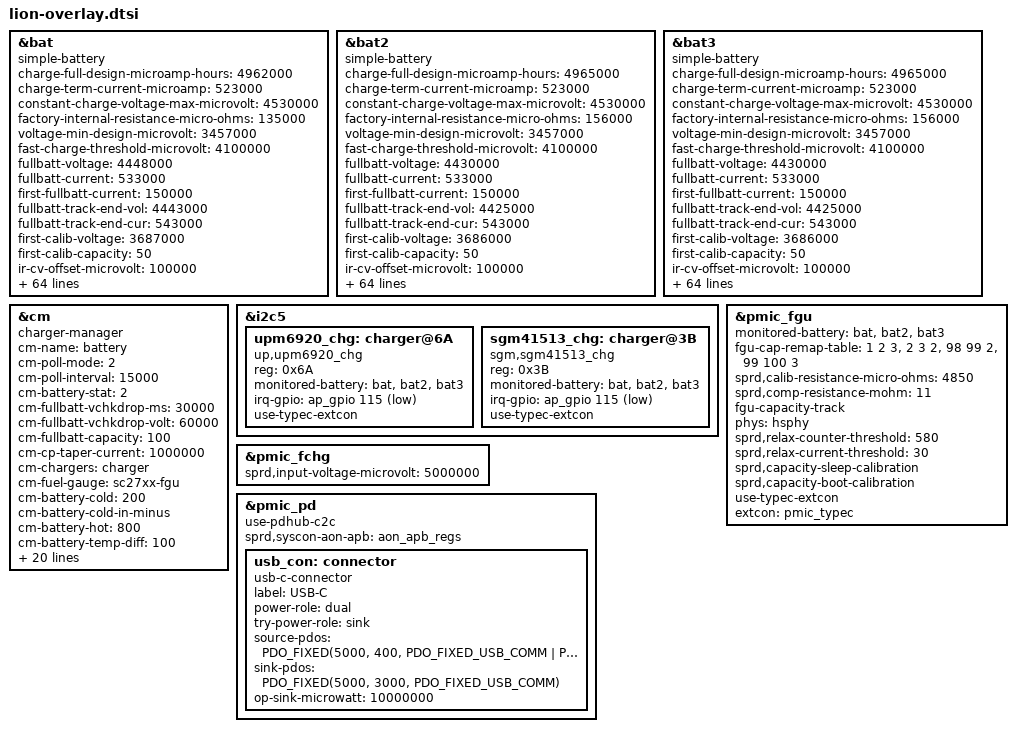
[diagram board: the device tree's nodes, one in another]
// SPDX-License-Identifier: GPL-2.0-only
/*
 * Unisoc Qogirl6 platform DTS file
 *
 * Copyright (C) 2020, Unisoc Inc.
 */

#include <dt-bindings/usb/pd.h>

&bat {
	compatible = "simple-battery";
	status = "okay";
	charge-full-design-microamp-hours = <4962000>;
	charge-term-current-microamp = <523000>;
	constant-charge-voltage-max-microvolt = <4530000>;
	factory-internal-resistance-micro-ohms = <135000>;
	voltage-min-design-microvolt = <3457000>;

	fast-charge-threshold-microvolt = <4100000>;
	fullbatt-voltage = <4448000>;
	fullbatt-current = <533000>;
	first-fullbatt-current = <150000>;
	fullbatt-track-end-vol = <4443000>;
	fullbatt-track-end-cur = <543000>;
	first-calib-voltage = <3687000>;
	first-calib-capacity = <50>;

	ir-cv-offset-microvolt = <100000>;
	ir-rc-micro-ohms = <0>;
	ir-us-upper-limit-microvolt = <4624000>;

	ocv-capacity-celsius = <25>;
	ocv-capacity-table-0 = <4448000 100>, <4384000 95>, <4331000 90>,
				<4273000 85>, <4212000 80>, <4153000 75>,
				<4096000 70>, <4044000 65>, <3997000 60>,
				<3945000 55>, <3890000 50>, <3859000 45>,
				<3835000 40>, <3815000 35>, <3799000 30>,
				<3777000 25>, <3754000 20>, <3730000 15>,
				<3697000 10>, <3687000 5>, <3400000 0>;
	voltage-temp-table = <1491668 600>,<1404493 650>,<1307738 700>,
				<1203814 750>, <1095466 800>, <986112 850>,
				<878559 900>,<775113 950>,<678460 1000>,
				<590240 1050>, <510773 1100>, <440156 1150>,
				<378279 1200>, <324561 1250>, <278079 1300>,
				<238260 1350>, <204267 1400>, <175208 1450>,
				<150460 1500>, <129410 1550>, <111497 1600>,
				<96484 1650>, <83710 1700>, <72772 1750>,
				<63423 1800>,<55444 1850>,<48599 1900>;

	capacity-temp-table = <45 96>, <25 100>, <10 100>, <0 93>, <(-10) 88>;
	resistance-temp-table = <45 88>, <25 100>, <10 143>, <0 976>, <(-10) 1049>;
	charge-sdp-current-microamp = <500000 500000>;
	charge-dcp-current-microamp = <3200000 3200000>;
	charge-cdp-current-microamp = <1500000 1500000>;
	charge-unknown-current-microamp = <1050000 1050000>;
	charge-fchg-current-microamp = <3480000 3000000>;

	cap-calib-energy-density-ocv-table = <3350000 3680000>, <4130000 4500000>;
	cap-track-energy-density-ocv-table = <3400000 3687000>;

	dcp-jeita-temp-table = <800 830 0 4200000>,<1000 1003 1000000 4200000>, <1100 1103 3200000 4500000>,
		<1150 1153 3200000 4500000>,<1450 1453 3200000 4530000>, <1600 1570 3200000 4200000>;
	sdp-jeita-temp-table = <800 803 0 4200000>,<1000 1003 500000 4200000>, <1100 1103 500000 4500000>,
		<1150 1153 500000 4500000>,<1450 1453 500000 4530000>, <1600 1570 500000 4200000>;
	cdp-jeita-temp-table = <800 830 0 4200000>,<1000 1030 1000000 4200000>, <1100 1103 1500000 4500000>,
		<1150 1153 1500000 4500000>,<1450 1453 1500000 4530000>, <1600 1570 1500000 4200000>;
	unknown-jeita-temp-table =<800 830 0 4200000>, <1000 1003 1000000 4200000>, <1100 1103 2000000 4500000>,
		<1150 1153 3000000 4500000>,<1450 1453 2000000 4530000>, <1600 1570 2000000 4200000>;
	fchg-jeita-temp-table =<800 830 0 4200000>,  <1000 1003 1000000 4200000>, <1100 1103 3000000 4500000>,
		<1150 1153 3480000 4500000>,<1450 1453 3480000 4530000>, <1600 1570 3480000 4200000>;
};

&bat2 {
	compatible = "simple-battery";
	status = "okay";
	charge-full-design-microamp-hours = <4965000>;
	charge-term-current-microamp = <523000>;
	constant-charge-voltage-max-microvolt = <4530000>;
	factory-internal-resistance-micro-ohms = <156000>;
	voltage-min-design-microvolt = <3457000>;

	fast-charge-threshold-microvolt = <4100000>;
	fullbatt-voltage = <4430000>;
	fullbatt-current = <533000>;
	first-fullbatt-current = <150000>;
	fullbatt-track-end-vol = <4425000>;
	fullbatt-track-end-cur = <543000>;
	first-calib-voltage = <3686000>;
	first-calib-capacity = <50>;

	ir-cv-offset-microvolt = <100000>;
	ir-rc-micro-ohms = <0>;
	ir-us-upper-limit-microvolt = <4624000>;

	ocv-capacity-celsius = <25>;
	ocv-capacity-table-0 = <4430000 100>, <4375000 95>, <4321000 90>,
				<4261000 85>, <4199000 80>, <4139000 75>,
				<4083000 70>, <4032000 65>, <3983000 60>,
				<3922000 55>, <3880000 50>, <3851000 45>,
				<3828000 40>, <3809000 35>, <3793000 30>,
				<3773000 25>, <3752000 20>, <3728000 15>,
				<3697000 10>, <3686000 5>, <3400000 0>;
	voltage-temp-table = <1491668 600>,<1404493 650>,<1307738 700>,
				<1203814 750>, <1095466 800>, <986112 850>,
				<878559 900>,<775113 950>,<678460 1000>,
				<590240 1050>, <510773 1100>, <440156 1150>,
				<378279 1200>, <324561 1250>, <278079 1300>,
				<238260 1350>, <204267 1400>, <175208 1450>,
				<150460 1500>, <129410 1550>, <111497 1600>,
				<96484 1650>, <83710 1700>, <72772 1750>,
				<63423 1800>,<55444 1850>,<48599 1900>;

	capacity-temp-table = <45 96>, <25 100>, <10 100>, <0 93>, <(-10) 86>;
	resistance-temp-table = <45 87>, <25 100>, <10 200>, <0 1018>, <(-10) 1117>;
	charge-sdp-current-microamp = <500000 500000>;
	charge-dcp-current-microamp = <3200000 3200000>;
	charge-cdp-current-microamp = <1500000 1500000>;
	charge-unknown-current-microamp = <1050000 1050000>;
	charge-fchg-current-microamp = <3480000 3000000>;

	cap-calib-energy-density-ocv-table = <3350000 3680000>, <4130000 4500000>;
	cap-track-energy-density-ocv-table = <3400000 3686000>;

	dcp-jeita-temp-table = <800 830 0 4200000>,<1000 1003 1000000 4200000>, <1100 1103 3200000 4500000>,
		<1150 1153 3200000 4500000>,<1450 1453 3200000 4530000>, <1600 1570 3200000 4200000>;
	sdp-jeita-temp-table = <800 803 0 4200000>,<1000 1003 500000 4200000>, <1100 1103 500000 4500000>,
		<1150 1153 500000 4500000>,<1450 1453 500000 4530000>, <1600 1570 500000 4200000>;
	cdp-jeita-temp-table = <800 830 0 4200000>,<1000 1030 1000000 4200000>, <1100 1103 1500000 4500000>,
		<1150 1153 1500000 4500000>,<1450 1453 1500000 4530000>, <1600 1570 1500000 4200000>;
	unknown-jeita-temp-table =<800 830 0 4200000>, <1000 1003 1000000 4200000>, <1100 1103 2000000 4500000>,
		<1150 1153 3000000 4500000>,<1450 1453 2000000 4530000>, <1600 1570 2000000 4200000>;
	fchg-jeita-temp-table =<800 830 0 4200000>,  <1000 1003 1000000 4200000>, <1100 1103 3000000 4500000>,
		<1150 1153 3480000 4500000>,<1450 1453 3480000 4530000>, <1600 1570 3480000 4200000>;
};

&bat3 {
	compatible = "simple-battery";
	status = "okay";
	charge-full-design-microamp-hours = <4965000>;
	charge-term-current-microamp = <523000>;
	constant-charge-voltage-max-microvolt = <4530000>;
	factory-internal-resistance-micro-ohms = <156000>;
	voltage-min-design-microvolt = <3457000>;

	fast-charge-threshold-microvolt = <4100000>;
	fullbatt-voltage = <4430000>;
	fullbatt-current = <533000>;
	first-fullbatt-current = <150000>;
	fullbatt-track-end-vol = <4425000>;
	fullbatt-track-end-cur = <543000>;
	first-calib-voltage = <3686000>;
	first-calib-capacity = <50>;

	ir-cv-offset-microvolt = <100000>;
	ir-rc-micro-ohms = <0>;
	ir-us-upper-limit-microvolt = <4624000>;

	ocv-capacity-celsius = <25>;
	ocv-capacity-table-0 = <4430000 100>, <4375000 95>, <4321000 90>,
				<4261000 85>, <4199000 80>, <4139000 75>,
				<4083000 70>, <4032000 65>, <3983000 60>,
				<3922000 55>, <3880000 50>, <3851000 45>,
				<3828000 40>, <3809000 35>, <3793000 30>,
				<3773000 25>, <3752000 20>, <3728000 15>,
				<3697000 10>, <3686000 5>, <3400000 0>;
	voltage-temp-table = <1491668 600>,<1404493 650>,<1307738 700>,
				<1203814 750>, <1095466 800>, <986112 850>,
				<878559 900>,<775113 950>,<678460 1000>,
				<590240 1050>, <510773 1100>, <440156 1150>,
				<378279 1200>, <324561 1250>, <278079 1300>,
				<238260 1350>, <204267 1400>, <175208 1450>,
				<150460 1500>, <129410 1550>, <111497 1600>,
				<96484 1650>, <83710 1700>, <72772 1750>,
				<63423 1800>,<55444 1850>,<48599 1900>;

	capacity-temp-table = <45 96>, <25 100>, <10 100>, <0 88>, <(-10) 76>;
	resistance-temp-table = <45 80>, <25 100>, <10 143>, <0 970>, <(-10) 1064>;
	charge-sdp-current-microamp = <500000 500000>;
	charge-dcp-current-microamp = <3200000 3200000>;
	charge-cdp-current-microamp = <1500000 1500000>;
	charge-unknown-current-microamp = <1050000 1050000>;
	charge-fchg-current-microamp = <3480000 3000000>;

	cap-calib-energy-density-ocv-table = <3350000 3680000>, <4130000 4500000>;
	cap-track-energy-density-ocv-table = <3400000 3686000>;

	dcp-jeita-temp-table = <800 830 0 4200000>,<1000 1003 1000000 4200000>, <1100 1103 3200000 4500000>,
		<1150 1153 3200000 4500000>,<1450 1453 3200000 4530000>, <1600 1570 3200000 4200000>;
	sdp-jeita-temp-table = <800 803 0 4200000>,<1000 1003 500000 4200000>, <1100 1103 500000 4500000>,
		<1150 1153 500000 4500000>,<1450 1453 500000 4530000>, <1600 1570 500000 4200000>;
	cdp-jeita-temp-table = <800 830 0 4200000>,<1000 1030 1000000 4200000>, <1100 1103 1500000 4500000>,
		<1150 1153 1500000 4500000>,<1450 1453 1500000 4530000>, <1600 1570 1500000 4200000>;
	unknown-jeita-temp-table =<800 830 0 4200000>, <1000 1003 1000000 4200000>, <1100 1103 2000000 4500000>,
		<1150 1153 3000000 4500000>,<1450 1453 2000000 4530000>, <1600 1570 2000000 4200000>;
	fchg-jeita-temp-table =<800 830 0 4200000>,  <1000 1003 1000000 4200000>, <1100 1103 3000000 4500000>,
		<1150 1153 3480000 4500000>,<1450 1453 3480000 4530000>, <1600 1570 3480000 4200000>;
};

&cm {
	compatible = "charger-manager";
	status = "okay";
	cm-name = "battery";
	cm-poll-mode = <2>;
	cm-poll-interval = <15000>;
	cm-battery-stat = <2>;

	cm-fullbatt-vchkdrop-ms = <30000>;
	cm-fullbatt-vchkdrop-volt = <60000>;
	cm-fullbatt-capacity = <100>;
	/*Charge pump target charge current*/
	cm-cp-taper-current = <1000000>;

	cm-chargers = "charger";
	//cm-chargers = "sgm41513_charger", "upm6920_charger";
	//cm-charge-pumps = "bq2597x-standalone";
	cm-fuel-gauge = "sc27xx-fgu";

	/* in deci centigrade */
	cm-battery-cold = <200>;
	cm-battery-cold-in-minus;
	cm-battery-hot = <800>;
	cm-battery-temp-diff = <100>;

	/* Allow charging for 6hr */
	cm-charging-max = <21600000>;
	/* recovery charging after stop charging 45min */
	cm-discharging-max = <2700000>;

	/* the interval to feed charger watchdog */
	cm-wdt-interval = <60>;

	/* drop voltage in microVolts to allow shutdown */
	cm-shutdown-voltage = <3100000>;

	/* when 99% of the time is exceeded, it will be forced to 100% */
	cm-tickle-time-out = <1500>;

	/* how much time to allow capacity change */
	cm-one-cap-time = <30>;

	cm-thermal-zone = "board-thmzone";

	/* when the safe charging voltage is exceeded, stop charging */
	cm-charge-voltage-max = <6500000>;
	cm-fast-charge-voltage-max = <10500000>;
	/* drop voltage in microVolts to restart charging */
	cm-charge-voltage-drop = <700000>;
	cm-fast-charge-voltage-drop = <700000>;

	/* sprd_fchg parameter */
	sprd,support-fchg;
	//sprd,support-pd-pps;
	sprd,pd-fixed-max-microwatt = <18000000>;

	monitored-battery = <&bat &bat2 &bat3>;
	cm-capacity-track;
	cm-keep-awake;

	phys = <&hsphy>;
	pd-extcon-enable;
	extcon = <&pmic_typec>, <&pmic_pd>;
	use-typec-extcon;
};

&i2c5 {
	#address-cells = <1>;
	#size-cells = <0>;

	status = "okay";

	upm6920_chg: charger@6A {
		compatible = "up,upm6920_chg";
		reg = <0x6A>;
		monitored-battery = <&bat &bat2 &bat3>;
		irq-gpio = <&ap_gpio 115 GPIO_ACTIVE_LOW>;
		use-typec-extcon;
	};

	sgm41513_chg: charger@3B {
                compatible = "sgm,sgm41513_chg";
                reg = <0x3B>;
                monitored-battery = <&bat &bat2 &bat3>;
                irq-gpio = <&ap_gpio 115 GPIO_ACTIVE_LOW>;
		use-typec-extcon;
        };

	/*bq2560x_chg: charger@6b {
		compatible = "ti,bq2560x_chg";
		reg = <0x6b>;
		monitored-battery = <&bat &bat2 &bat3>;
		irq-gpio = <&ap_gpio 115 GPIO_ACTIVE_LOW>;
		vddvbus:otg-vbus {
			regulator-name = "vddvbus";
		};
	};*/
};

&pmic_fgu {
	monitored-battery = <&bat &bat2 &bat3>;
	fgu-cap-remap-table = <1 2 3>, <2 3 2>, <98 99 2>, <99 100 3>;
	sprd,calib-resistance-micro-ohms = <4850>;
	sprd,comp-resistance-mohm = <11>;

	fgu-capacity-track;
	phys = <&hsphy>;

	sprd,relax-counter-threshold = <580>;
	sprd,relax-current-threshold = <30>;
	sprd,capacity-sleep-calibration;

	sprd,capacity-boot-calibration;
	use-typec-extcon;
	extcon = <&pmic_typec>;
};

&pmic_fchg {
	status = "okay";
	sprd,input-voltage-microvolt = <5000000>;
};

&pmic_pd {
	status = "okay";
	//vbus-supply = <&vddvbus>;
	use-pdhub-c2c;
	sprd,syscon-aon-apb = <&aon_apb_regs>;
	usb_con: connector {
		compatible = "usb-c-connector";
		label = "USB-C";
		power-role = "dual";
		try-power-role = "sink";
		source-pdos = <PDO_FIXED(5000, 400, PDO_FIXED_USB_COMM |
				PDO_FIXED_DUAL_ROLE | PDO_FIXED_DATA_SWAP)>;
		sink-pdos = <PDO_FIXED(5000, 3000, PDO_FIXED_USB_COMM)>;
		op-sink-microwatt = <10000000>;
	};
};
